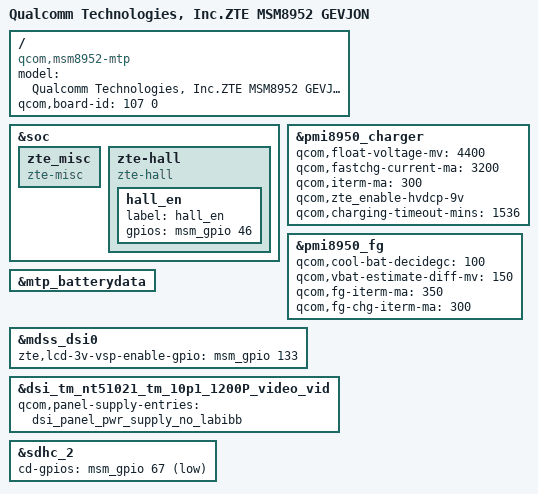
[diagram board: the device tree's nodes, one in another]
/*
 * Copyright (c) 2015, The Linux Foundation. All rights reserved.
 *
 * This program is free software; you can redistribute it and/or modify
 * it under the terms of the GNU General Public License version 2 and
 * only version 2 as published by the Free Software Foundation.
 *
 * This program is distributed in the hope that it will be useful,
 * but WITHOUT ANY WARRANTY; without even the implied warranty of
 * MERCHANTABILITY or FITNESS FOR A PARTICULAR PURPOSE.  See the
 * GNU General Public License for more details.
 */

/dts-v1/;

#include "msm8952-mtp.dtsi"
#include "zte-msm8952-gevjon.dtsi"
#include "dsi-panel-zte-tm-nt51021-tm-10p1-1200p-video.dtsi"

/ {
	model = "Qualcomm Technologies, Inc.ZTE MSM8952 GEVJON";
	compatible = "qcom,msm8952-mtp", "qcom,msm8952", "qcom,mtp";
	qcom,board-id= <107 0>;
};
&soc {
        zte_misc {
                compatible = "zte-misc";
        };
        zte-hall {
                compatible = "zte-hall";
                hall_en{
                        label = "hall_en";
                        gpios = <&msm_gpio 46 0x0>;
		};
        };
};
&pmi8950_charger {
	qcom,float-voltage-mv = <4400>;
	qcom,fastchg-current-ma = <3200>;
	qcom,iterm-ma = <300>;
	qcom,zte_enable-hvdcp-9v;
	qcom,charging-timeout-mins = <1536>;
};
&pmi8950_fg{
	qcom,cool-bat-decidegc = <100>;
	qcom,vbat-estimate-diff-mv = <150>;
	qcom,fg-iterm-ma = <350>;
	qcom,fg-chg-iterm-ma = <300>;
};
&mtp_batterydata {
		#include "ZTE_P895U90_9070mAh_batterydata.dtsi"
};

&mdss_dsi0 {

	zte,lcd-3v-vsp-enable-gpio = <&msm_gpio 133 0>;
};
&dsi_tm_nt51021_tm_10p1_1200P_video_vid {
	qcom,panel-supply-entries = <&dsi_panel_pwr_supply_no_labibb>;
	//qcom,ulps-enabled;
};

&sdhc_2 {
	cd-gpios = <&msm_gpio 67 0x1>;
};


